# ECM3531 register map
Vendor: EtaCompute; Series: ECM35xx; File version: 1.0.0
CPU: CM3 r1p1, little endian, MPU, no FPU, 3 interrupt priority bits
Registers are 32-bit, read-write, reset 0x0 unless marked. A register's access mark holds for its fields unless they carry their own. Offsets are from the block's base; [hi:lo] are bit positions; 'fields as' and 'values as' point back to an identical list.

## RTC — The real time clock (RTC) is part of the Always On block. In addition to maintaining the real time epoch for the SOC, it also contains all of the control registers of AO block, e.g. registers for the power controller.
Base 0x50010000
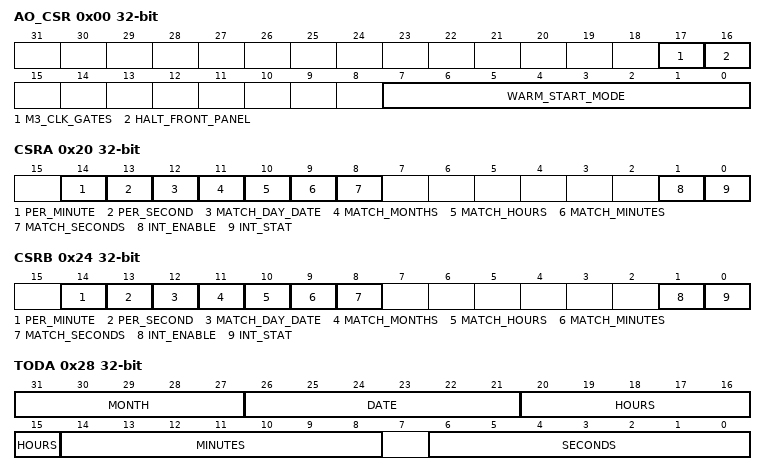
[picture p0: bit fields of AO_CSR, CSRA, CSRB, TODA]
0x00 AO_CSR — Configuration and status bits for the always on block, which includes the RTC, WDT, POWER, etc.
  [17] M3_CLK_GATES — Set this bit to one to keep the M3 clocks running if they would normally be stalled.
  [16] HALT_FRONT_PANEL — Set this bit to one to halt the AO front panel and tristate its output pin for low power reasons.
  [7:0] WARM_START_MODE — BOOTROM assumes 0x00 is a cold start and any non-zero value is a warm start. This value is also visible in the external status register in the GPIO inside the M3 complex. NOTE: a value written to this value survives all resets except the master POR that happens at true first chip power up.
0x20 CSRA — Configuration and status bits for the real time clock (RTC).
  [14] PER_MINUTE — Set to 1 to interrrupt every minute.
  [13] PER_SECOND — Set to 1 to interrrupt every second.
  [12] MATCH_DAY_DATE — Set to 1 to match the day or date.
  [11] MATCH_MONTHS — Set to 1 to match the current month.
  [10] MATCH_HOURS — Set to 1 to match the current hour.
  [9] MATCH_MINUTES — Set to 1 to match the current minutes.
  [8] MATCH_SECONDS — Set to 1 to match the current minutes.
  [1] INT_ENABLE — Interrupt enable bit for ALARM A comparison interrupts.
  [0] INT_STAT — Interrupt status bit for ALARM A comparison (set by an exact match). Write one to this bit to clear it.
0x24 CSRB — Configuration and status bits for the real time clock (RTC).
  [14] PER_MINUTE — Set to 1 to interrrupt every minute.
  [13] PER_SECOND — Set to 1 to interrrupt every second.
  [12] MATCH_DAY_DATE — Set to 1 to match the day or date.
  [11] MATCH_MONTHS — Set to 1 to match the current month.
  [10] MATCH_HOURS — Set to 1 to match the current hour.
  [9] MATCH_MINUTES — Set to 1 to match the current minutes.
  [8] MATCH_SECONDS — Set to 1 to match the current minutes.
  [1] INT_ENABLE — Interrupt enable bit for ALARM B comparison interrupts.
  [0] INT_STAT — Interrupt status bit for ALARM B comparison (set by an exact match). Write one to this bit to clear it.
0x28 TODA — Current time of day as recorded in the RTC. NOTE: This register must be written 32 bits at a time. The counter updates on the last byte written.
  [31:27] MONTH — Current Value of Month (1..12) in the time of day.
  [26:21] DATE — Current Value of Date (0..3,0..9) in the time of day.
  [20:15] HOURS — Current Value of Hours (0..2,0..9) in the time of day.
  [14:8] MINUTES — Current Value of Minutes (0..5,0..9) in the time of day.
  [6:0] SECONDS — Current Value of Seconds(0..5,0..9 in the time of day.
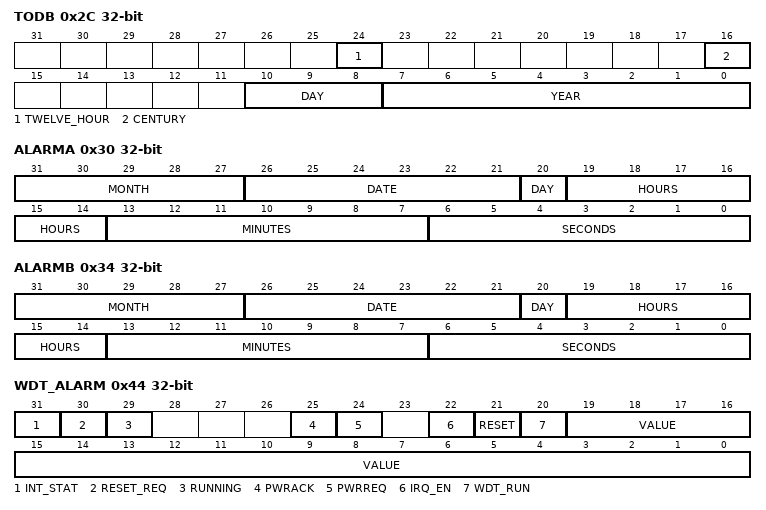
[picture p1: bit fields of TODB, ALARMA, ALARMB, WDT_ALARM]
0x2C TODB — Current time of day as recorded in the RTC. NOTE: Write to Time of Day B (TODB) before writing to Time of Day A (TODA). This register must be written 32 bits at a time. The counter updates on the last byte written.
  [24] TWELVE_HOUR — Set to 1 for 12 hour mode. Set to 0 for 24 hour mode.
  [16] CENTURY — Current Value of Century (0..1) in the time of day.
  [10:8] DAY — Current Value of Year (1..7) in the time of day.
  [7:0] YEAR — Current Value of Year (0..9,0..9) in the time of day.
0x30 ALARMA — ALARM value to match against the current time of day. NOTE: ALARM A interrupt should not be enabled when this register is written. The ALARM A interrupt should be cleared after this register is written.
  [31:27] MONTH — Value of Month (1..12) to be compared against the time of day.
  [26:21] DATE — Value of Date (0..3,0..9) to be compared against the time of day.
  [20] DAY — Set to one to match alarm on day instead of date.
  [19:14] HOURS — Value of Hours (0..2,0..9) to be compared against the time of day.
  [13:7] MINUTES — Value of Minutes (0..5,0..9) to be compared against the time of day.
  [6:0] SECONDS — Value of Seconds(0..5,0..9) to be compared against the time of day.
0x34 ALARMB — ALARM value to match against the current time of day. NOTE: ALARM B interrupt should not be enabled when this register is written. The ALARM B interrupt should be cleared after this register is written.
  fields as ALARMA
0x40 WDT_COUNTER — WDT COUNTER: This register decrements toward zero. If it gets there and resets are enabled then a WDT is issued. This can have the aeffect of waking up the peripheral block and then the M3. The peripheral rstgen status will reflect both a POR and a WDT reset cause in this case. If an interrupt occurs it can also wake up the peripheral block and M3. If the interrupt causes the wake up then it will also be forwarded to the NVIC once the M3 is powered up and out of reset. Write any value to byte 0 of this register to cause the counter to be reloaded from WDT_RELOAD register.
  [19:0] COUNT — Current Value of WDT COUNTER
0x44 WDT_ALARM — WDT ALARM: The contents of this register are matched agains the counter. If the counter value falls below the alarm value then a WDT interrupt status bit is set to one. If this interrupt is enable to cause a power up then the WDT interrupt can power up the peripheral block and the M3.
  [31] INT_STAT — This bit is set to one if a watch dog timer alarm interrupt has been detected. It is clear by writing a one to this bit.
    1=CLEAR (Clear the watch dog timer interrupt status bit.)
  [30] RESET_REQ — This bit is set to one if the watch dog timer counter reaches zero. If the RESET enable bit is also a 1 then this will trigger the cascade of powering up the M3 and then giving it a watch dog timer reset. Firmware can write this bit to either zero or one.
    0=CLEAR (Clear the watch dog timer reset request bit.); 1=SET (Set the watch dog timer reset request bit.)
  [29] RUNNING ro — This bit is set to one if the watch dog timer counter running (decrementing). Clear the enable WDT operation bit reset this read only bit.
  [25] PWRACK ro — This read only bit shows the state of the power up acknowledge sent from the power controller.
  [24] PWRREQ ro — This read only bit shows the state of the power up request sent to the power controller.
  [22] IRQ_EN — Set to one to enable the WDT to interupt the M3. Note an interrupt request will power up the M3 if necessary.
    1=ENABLE (Enable the watch dog timer interrupt.); 0=DISABLE (Disable the watch dog timer interrupt.)
  [21] RESET — Set to one to enable the WDT to reset the chip.
    1=ENABLE (Enable watch dog timer resets.); 0=DISABLE (Disable watch dog timer resets.)
  [20] WDT_RUN — Set to one to enable WDT operation.
    1=ENABLE (Enable the watch dog timer.); 0=DISABLE (Disable the watch dog timer.)
  [19:0] VALUE — Alarm value to compare against the WDT couner.
0x48 WDT_RELOAD — This register holds the value to be reloaded into the counter for each restart of the WDT. Anytime byte 0 of the counter is written then the entire counter is reloaded from this value. In addition, writing to this registers loads the counter from the data written to the RELOAD register. For normal operation, set up the bits in the ALARM register and then write the reload value to this register. This will start the watchdog operation.
  [19:0] VALUE — Load this value into the counter each time a write is directed to byte zero of the counter.
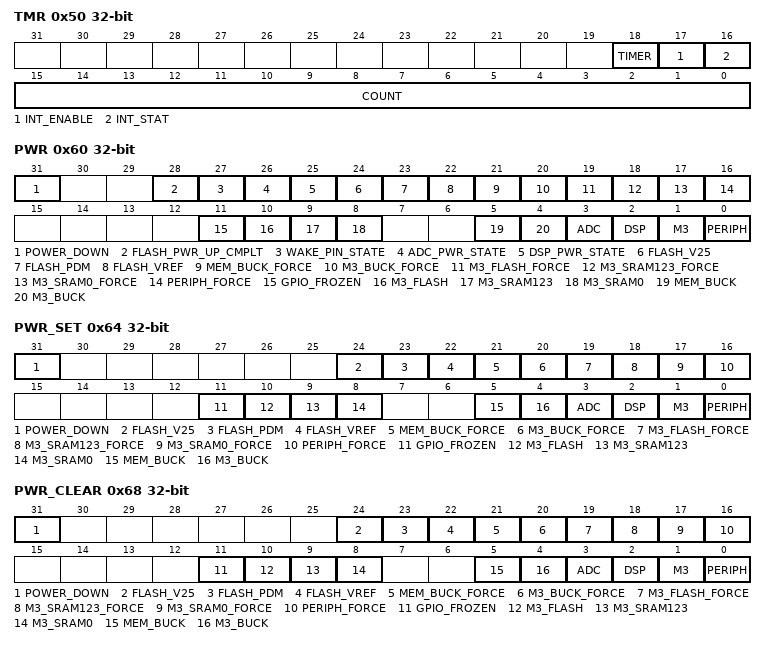
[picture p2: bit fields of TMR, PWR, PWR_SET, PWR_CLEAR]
0x50 TMR — This register controls the 1KHz timer in the always on block. This timer can be used to wake up the M3 from a complete power down state. If the M3 is powered up at the time this timer interrupts, then the M3 simply receives a timer interrupt. NOTE: if the M3 is awakened from a power down state it will receive a full POR restart before it gets the interrupt. The NVIC interrupt enable will have been reset so the interrupt will not fire until the NVIC is re-enabled.
  [18] TIMER — Write a one to this bit to enable the counter to decrement.
    0=STOP (Stop the timer.); 1=RUN (Let the timer run.)
  [17] INT_ENABLE — Write a one to this bit to enable the interrupt status bit to cause an interrupt to the M3 and if necessary, a power up of the M3.
  [16] INT_STAT — This bit is set when the counter decrements from one to zero. It is cleared by writing a one to it.
  [15:0] COUNT — Values written to this bit field update the counter. This counter decrements at a 1KHz rate. When it reaches zero, then its interrupt is generated.
0x60 PWR — This register holds the bit fields that control the power state of the SOC. The default operation when the POWER_DOWN bit is written to one is to turn off ALL power domains except the always on domain. The default behavior on power up is to power up everything but the ADC and the DSP. This can be overridden somewhat using the force bits in this register. The general should only modify the force bits and write to the power down bit. NOTE: the apparent reset or default state of these bits will be different depending on whether the M3 is starting up from a cold start or a warm start.
  [31] POWER_DOWN wo — Write a one to this bit or use the set register to set this bit. Either operation will initiate a power down sequence that will power down the M3 and all of its memories that are to be powered off. If the peripheral power domain is not forced to remain on then it will also be powered down in response to setting this bit. Shutting down the peripheral domain will power down the ADC.
  [28] FLASH_PWR_UP_CMPLT ro — This read only bit indicates when the flash VREF has fully charged and the PDM signal has been removed.
  [27] WAKE_PIN_STATE ro — This read only bit indicates the current value presented to the WAKE pin of the chip. The WAKE pin is one thing that can wake up the M3.
  [26] ADC_PWR_STATE ro — This read only bit indicates the current power state of the ADC. In general, the power on of the ADC will appear to be instantaneous to an M3 program. This bit provides a mechanism to interlock the firmware power up code.
  [25] DSP_PWR_STATE ro — This read only bit indicates the current power state of the DSP. In general, the power on of the DSP will appear to be instantaneous to an M3 program. This bit provides a mechanism to interlock the firmware power up code.
  [24] FLASH_V25 — Set this bit to zero to turn off the flash FLASH 2.5V. Set this bit to one to turn on the FLASH 2.5V.
  [23] FLASH_PDM — Set this bit to zero to turn off the flash PDM signal.
  [22] FLASH_VREF — Set this bit to zero to turn off the voltage reference for the flash.
  [21] MEM_BUCK_FORCE — Write a one to this bit to force the MEM BUCK converter to remain ON even when the M3 itself is powered OFF. The default behavior is to power down the MEM BUCK converter when the M3 powers off.
  [20] M3_BUCK_FORCE — Write a one to this bit to force the M3 BUCK converter to remain ON even when the M3 itself is powered OFF. The default behavior is to power down the M3 BUCK converter when the M3 powers off.
  [19] M3_FLASH_FORCE — Write a one to this bit to force the M3 FLASH power domain to remain OFF even when the M3 itself is powered back up.
  [18] M3_SRAM123_FORCE — Write a one to this bit to force the M3 SRAM123 power domain to remain ON even when the M3 itself is powered down.
  [17] M3_SRAM0_FORCE — Write a one to this bit to force the M3 SRAM0 power domain to remain ON even when the M3 itself is powered down.
  [16] PERIPH_FORCE — Write a one to this bit to force the PERIPH power domain to remain ON even when the M3, DSP, and ADC are powered down.
  [11] GPIO_FROZEN — Write a zero to this bit to force the GPIO latch in the peripheral block to flow through to the pins again. The GPIO data out enable out type signals are frozen in their final state before the M3 is reset, isolated and powered. This happens automatically on a power down of the M3. When the M3 comes back in a warm start the GPIO latches are frozen until firmware clears this bit. A cold start does not set hthis bit.
  [10] M3_FLASH — Write a zero to this bit to turn off power in the M3 FLASH power domain. This bit is set automatically at initial power provisioning. Can be turned back on automatically in response to a wake up event. In addition, this bit can be forced to remain off even if the M3 is powered up from a wake event. This is useful for various power saving modes where the program is running as a warm start program in one or more of the SRAMs.
  [9] M3_SRAM123 — Write a zero to this bit to turn off power in the M3 SRAM123 power domain. This bit is set automatically at initial power provisioning. Can be turned back on automatically in response to a wake up event. In addition, this bit can be forced to remain on even if the M3 is powered down.
  [8] M3_SRAM0 — Write a zero to this bit to turn off power in the M3 SRAM0 power domain. This bit is set automatically at initial power provisioning. Can be turned back on automatically in response to a wake up event. In addition, this bit can be forced to remain on even if the M3 is powered down.
  [5] MEM_BUCK — Write a zero to this bit to turn off the MEM BUCK converter.
  [4] M3_BUCK — Write a zero to this bit to turn off the M3 BUCK converter.
  [3] ADC — Write a zero to this bit to turn off power in the ADC power domain. This bit is NOT set automatically at initial power provisioning. It can *NOT* be turned back on automatically in response to a wake up event. It can, however, be left on during an M3 power request. This would only make since if peripheral power were left on. Thus turning off the peripheral power will this area of the chip off as well.
  [2] DSP — Write a zero to this bit to turn off power in the DSP power domain. Writing zero will also power down the DSP SRAMs. This bit is NOT set automatically at initial power provisioning. It can *NOT* be turned back on automatically in response to a wake up event. It is ALWAYS automatically turned off as part of every power down sequence. This bit also controls the power state of the DSP PMEM, XMEM, and YMEM.
  [1] M3 — Write a zero to this bit to turn off power in the M3 power domain. Writing zero will also power down the M3 SRAMs, Flash, and Bootrom. This bit is set automatically at initial power provisioning. Can be turned back on automatically in response to a wake up event.
  [0] PERIPH — Write a zero to this bit to turn off power in the peripheral power domain. This bit is set automatically at initial power provisioning. Can be turned back on automatically in response to a wake up event. Note that turning on this bit will also turn on the high frequency oscillator (HFO).
0x64 PWR_SET — The bits in this register correspond to bits in the PWR register. Writing a one to one of the bits in this register cause the correponding bit in the PWR register to be set. These bits always read back as zero.
  [31] POWER_DOWN wo — Writing a one to this bit will initiate a power down sequence.
  [24] FLASH_V25 wo — Writing a one to this bit will set the corresponding bit in the PWR register.
  [23] FLASH_PDM wo — Writing a one to this bit will set the corresponding bit in the PWR register.
  [22] FLASH_VREF wo — Set this bit to zero to turn of the voltage reference for the flash.
  [21] MEM_BUCK_FORCE wo — Writing a one to this bit will set the corresponding bit in the PWR register.
  [20] M3_BUCK_FORCE wo — Writing a one to this bit will set the corresponding bit in the PWR register.
  [19] M3_FLASH_FORCE wo — Writing a one to this bit will set the corresponding bit in the PWR register.
  [18] M3_SRAM123_FORCE wo — Writing a one to this bit will set the corresponding bit in the PWR register.
  [17] M3_SRAM0_FORCE wo — Writing a one to this bit will set the corresponding bit in the PWR register.
  [16] PERIPH_FORCE wo — Writing a one to this bit will set the corresponding bit in the PWR register.
  [11] GPIO_FROZEN wo — Writing a one to this bit will set the corresponding bit in the PWR register.
  [10] M3_FLASH wo — Writing a one to this bit will set the corresponding bit in the PWR register.
  [9] M3_SRAM123 wo — Writing a one to this bit will set the corresponding bit in the PWR register.
  [8] M3_SRAM0 wo — Writing a one to this bit will set the corresponding bit in the PWR register.
  [5] MEM_BUCK — Write a one to this bit will set the corresponding bit in the PWR register.
  [4] M3_BUCK — Write a one to this bit will set the corresponding bit in the PWR register.
  [3] ADC wo — Writing a one to this bit will set the corresponding bit in the PWR register.
  [2] DSP wo — Writing a one to this bit will set the corresponding bit in the PWR register.
  [1] M3 wo — Writing a one to this bit will set the corresponding bit in the PWR register.
  [0] PERIPH wo — Writing a one to this bit will set the corresponding bit in the PWR register.
0x68 PWR_CLEAR — The bits in this register correspond to bits in the PWR register. Writing a one to one of the bits in this register cause the correponding bit in the PWR register to be cleared. These bits always read back as zero.
  [31] POWER_DOWN wo — Writing a one to this bit will have no effect.
  [24] FLASH_V25 wo — Writing a one to this bit will clear the corresponding bit in the PWR register.
  [23] FLASH_PDM wo — Writing a one to this bit will clear the corresponding bit in the PWR register.
  [22] FLASH_VREF wo — Set this bit to zero to turn of the voltage reference for the flash.
  [21] MEM_BUCK_FORCE — Writing a one to this bit will clear the corresponding bit in the PWR register.
  [20] M3_BUCK_FORCE — Writing a one to this bit will clear the corresponding bit in the PWR register.
  [19] M3_FLASH_FORCE wo — Writing a one to this bit will clear the corresponding bit in the PWR register.
  [18] M3_SRAM123_FORCE wo — Writing a one to this bit will clear the corresponding bit in the PWR register.
  [17] M3_SRAM0_FORCE wo — Writing a one to this bit will clear the corresponding bit in the PWR register.
  [16] PERIPH_FORCE wo — Writing a one to this bit will clear the corresponding bit in the PWR register.
  [11] GPIO_FROZEN wo — Writing a one to this bit will clear the corresponding bit in the PWR register.
  [10] M3_FLASH wo — Writing a one to this bit will clear the corresponding bit in the PWR register.
  [9] M3_SRAM123 wo — Writing a one to this bit will clear the corresponding bit in the PWR register.
  [8] M3_SRAM0 wo — Writing a one to this bit will clear the corresponding bit in the PWR register.
  [5] MEM_BUCK — Write a one to this bit will clear the corresponding bit in the PWR register.
  [4] M3_BUCK — Write a one to this bit will clear the corresponding bit in the PWR register.
  [3] ADC wo — Writing a one to this bit will clear the corresponding bit in the PWR register.
  [2] DSP wo — Writing a one to this bit will clear the corresponding bit in the PWR register.
  [1] M3 wo — Writing a one to this bit will clear the corresponding bit in the PWR register.
  [0] PERIPH wo — Writing a one to this bit will clear the corresponding bit in the PWR register.
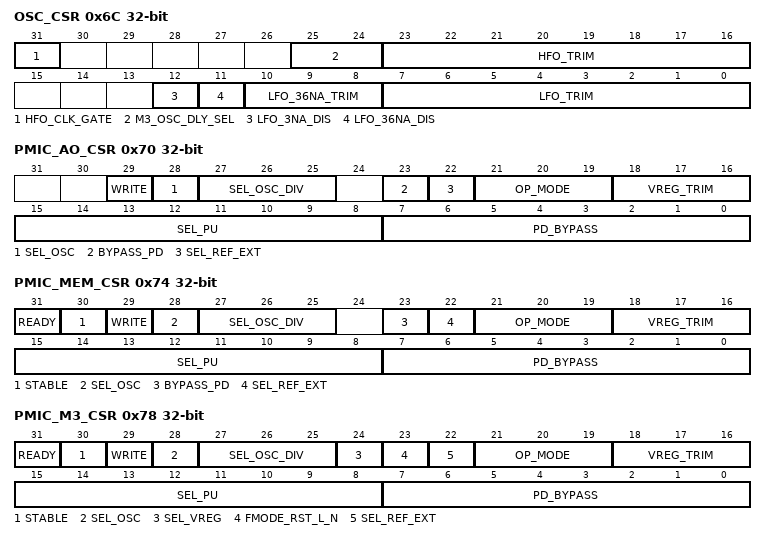
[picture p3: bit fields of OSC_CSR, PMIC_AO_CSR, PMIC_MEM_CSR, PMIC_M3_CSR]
0x6C OSC_CSR — Control bits headed either for the 8MHz high frequency osciallator (HFO) or to the 32KHz low frequency oscillator (LFO).
  [31] HFO_CLK_GATE — Writing a one to this bit will stop the HFO clock while it's trim values are changed. Firmware has to stop this clock when changing the value in the HFO_TRIM and HFO_TRIM_DIV bit fields.
  [25:24] M3_OSC_DLY_SEL — These settings will be defined after characterization.
  [23:16] HFO_TRIM — These settings will be defined after characterization.
  [12] LFO_3NA_DIS — Set to one to disable voltage mode operation reference current.
  [11] LFO_36NA_DIS — Set to one to disable current mode operation reference current.
  [10:8] LFO_36NA_TRIM — Set the current mode reference trim value into this bit field. These settings will be defined after characterization.
  [7:0] LFO_TRIM — Output frequency trim settings. These settings will be defined after characterization.
0x70 PMIC_AO_CSR — Control bits headed for the PMIC. These are all captured in the PMIC by LOAD_L. The LOAD_L pulse is automatically generated whenever this register is written, provided that the WRITE bit is written as a one on the same cycle.
  [29] WRITE wo — Set this write only bit to one to issue a LOAD_L pulse to the PMIC causing it to capture the values from this register.
  [28] SEL_OSC — Selects which clock source to use for the divider in the peripheral which can drive the AO PMIC.
    0=HFO (Select the 8MHz HFO clock source into the divider.); 1=XTAL (Select the 32KHz clock source into the divider.)
  [27:25] SEL_OSC_DIV — Selects which HFO divider to use as an external clock for this PMIC.
    0=1BY1 (Divider is set for 1 divided by 1, i.e. 1MHz or 32768Hz.); 1=1BY2 (Divider is set for 1 divided by 2, i.e. 500KHz or 16384Hz.); 2=1BY4 (Divider is set for 1 divided by 4, i.e. 250KHz or 8192Hz.); 3=1BY8 (Divider is set for 1 divided by 8, i.e. 125KHz or 4096Hz.); 4=1BY16 (Divider is set for 1 divided by 16, i.e. 62500Hz or 2048Hz.); 5=1BY32 (Divider is set for 1 divided by 32, i.e. 1024Hz (only 32KHz source).); 6=1BY64 (Divider is set for 1 divided by 64, i.e. 512Hz (only 32KHz source).); 7=1BY128 (Divider is set for 1 divided by 128, i.e. 256Hz (only 32KHz source).)
  [23] BYPASS_PD — Inside the PMIC, this value bypasses the normal internal generation of the pull down pulse width. It substitutes the PD_BYPASS value instead.
    0=NORMAL (Select normal operation in which PMIC controls pull down pulse width.); 1=OVERRIDE (OVERRIDE automatic control function in PMIC.)
  [22] SEL_REF_EXT — Inside the PMIC, this value selects between REF_CLK_PWR_UP and REF_CLK input to the PMIC.
    0=INITIAL (Select initial operation by using the internal reference clock.); 1=NORMAL (Select the reference clock that is supplied to the PMIC block.)
  [21:19] OP_MODE — Inside the PMIC, this value selects between frequency and voltage mode and selects the target voltage in voltage mode.
    0=VOLTAGE_600MV (Select voltage mode and target 600mV.); 1=VOLTAGE_700MV (Select voltage mode and target 700mV.); 2=VOLTAGE_900MV (Select voltage mode and target 900mV.); 3=VOLTAGE_1200MV (Select voltage mode and target 1200mV.); 4=FREQUENCY_MODE (Select frequency mode with VMIN and VMAX protection.); 5=FREQ_VMIN (Select frequency mode with VMIN protection.); 6=FREQ_VMAX (Select frequency mode with maximum voltage limiting to XXXmV.); 7=FREQUENCY_NO_VLIM (Select frequency mode with NO minimum or maximum voltage limiting.)
  [18:16] VREG_TRIM — Inside the PMIC, this value selects a trim offset for the target voltage.
  [15:8] SEL_PU — Inside the PMIC, this value controls the switch drivers UP pulse width. It defaults to the 900mV setting at reset. This value is ignored during initialization.
  [7:0] PD_BYPASS — Inside the PMIC, this value controls the switch drivers DOWN pulse width. This value is only used in the driver if BYPASS_PD is also a one.
0x74 PMIC_MEM_CSR — Control bits headed for the PMIC. These are all captured in the PMIC by LOAD_L. The LOAD_L pulse is automatically generated whenever this register is written, provided that the WRITE bit is written as a one on the same cycle.
  [31] READY ro — The PMIC reports not ready, 0x0, whenever it is powered up. Firmware can use this bit to know when the target voltage has been reached.
  [30] STABLE ro — This bit reports not stable, 0x0, whenever its target voltage is changed by firmware. Firmware can use this bit to know when the target voltage has been reached.
  [29] WRITE wo — Set this write only bit to one to issue a LOAD_L pulse to the PMIC causing it to capture the values from this register.
  [28] SEL_OSC — Selects which clock source to use for the divider in the peripheral which can drive the MEM PMIC.
    values as PMIC_AO_CSR.SEL_OSC
  [27:25] SEL_OSC_DIV — Selects which HFO divider to use as an external clock for this PMIC.
    values as PMIC_AO_CSR.SEL_OSC_DIV
  [23] BYPASS_PD — Inside the PMIC, this value bypasses the normal internal generation of the pull down pulse width. It substitutes the PD_BYPASS value instead.
    values as PMIC_AO_CSR.BYPASS_PD
  [22] SEL_REF_EXT — Inside the PMIC, this value selects between REF_CLK_PWR_UP and REF_CLK input to the PMIC.
    values as PMIC_AO_CSR.SEL_REF_EXT
  [21:19] OP_MODE — Inside the PMIC, this value selects between frequency and voltage mode and selects the target voltage in voltage mode.
    values as PMIC_AO_CSR.OP_MODE
  [18:16] VREG_TRIM — Inside the PMIC, this value selects a trim offset for the target voltage.
  [15:8] SEL_PU — Inside the PMIC, this value controls the switch drivers UP pulse width. It defaults to the 900mV setting at reset. This value is ignored during initialization.
  [7:0] PD_BYPASS — Inside the PMIC, this value controls the switch drivers DOWN pulse width. This value is only used in the driver if BYPASS_PD is also a one.
0x78 PMIC_M3_CSR — Control bits headed for the PMIC. These are all captured in the PMIC by LOAD_L. The LOAD_L pulse is automatically generated whenever this register is written, provided that the WRITE bit is written as a one on the same cycle.
  [31] READY ro — The PMIC reports not ready, 0x0, whenever it is powered up. Firmware can use this bit to know when the target voltage has been reached.
  [30] STABLE ro — This bit reports not stable, 0x0, whenever its target voltage is changed by firmware. Firmware can use this bit to know when the target voltage has been reached.
  [29] WRITE wo — Set this write only bit to one to issue a LOAD_L pulse to the PMIC causing it to capture the values from this register.
  [28] SEL_OSC — Selects which clock source to use for the divider in the peripheral which can drive the M3 PMIC.
    values as PMIC_AO_CSR.SEL_OSC
  [27:25] SEL_OSC_DIV — Selects which HFO divider to use as an external clock for this PMIC.
    values as PMIC_AO_CSR.SEL_OSC_DIV
  [24] SEL_VREG — Set to one to monitor VDD_M3 after the power switch. Set to zero to monitor before the switch.
    0=REG_OUTPUT (Select monitoring the regulator output.); 1=POST_SWITCH (Select monitoring the voltage after it is switched.)
  [23] FMODE_RST_L_N — Inside the PMIC, this value forces a reset to the frequency mode counters. This should be 0 before switching to frequency mode. After the switch this should be set to one.
    1=RESET (Select RESET operation for the frequency mode of operation.); 0=NORMAL (Select NORMAL operation for the frequency mode of operation.)
  [22] SEL_REF_EXT — Inside the PMIC, this value selects between REF_CLK_PWR_UP and REF_CLK input to the PMIC.
    values as PMIC_AO_CSR.SEL_REF_EXT
  [21:19] OP_MODE — Inside the PMIC, this value selects between frequency and voltage mode and selects the target voltage in voltage mode.
    values as PMIC_AO_CSR.OP_MODE
  [18:16] VREG_TRIM — Inside the PMIC, this value selects a trim offset for the target voltage.
  [15:8] SEL_PU — Inside the PMIC, this value controls the switch drivers UP pulse width. It defaults to the 900mV setting at reset. This value is ignored during initialization.
  [7:0] PD_BYPASS — Inside the PMIC, this value controls the switch drivers DOWN pulse width. This value is only used in the driver if BYPASS_PD is also a one.
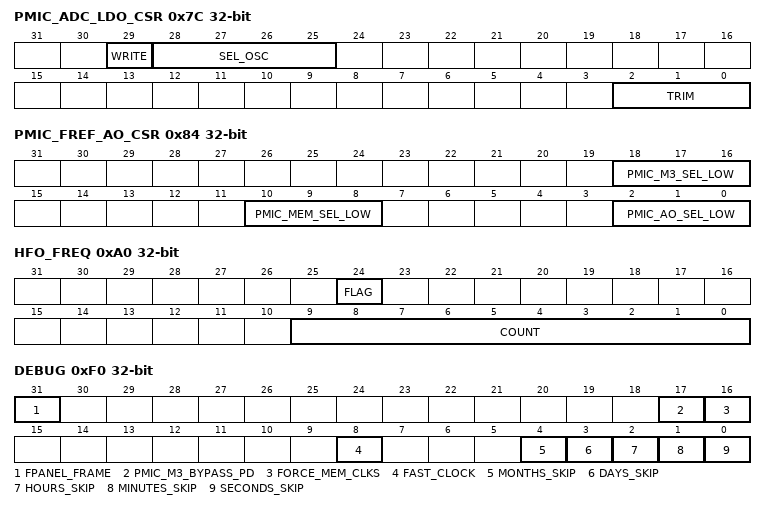
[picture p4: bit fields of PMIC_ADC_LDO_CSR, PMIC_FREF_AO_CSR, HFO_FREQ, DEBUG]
0x7C PMIC_ADC_LDO_CSR — Control bits headed for the ADC LDO. These are all captured in the LDO by LOAD_L. The LOAD_L pulse is automatically generated whenever this register is written, provided that the WRITE bit is written as a one on the same cycle.
  [29] WRITE wo — Set this write only bit to one to issue a LOAD_L pulse to the PMIC causing it to capture the values from this register.
  [28:25] SEL_OSC — Selects which HFO divider to use as an external clock for this digital LDO. FIXME BRYAN set enums for divisions.
  [2:0] TRIM — Selects a trim value for the ADC LDO. Note this value has to be loaded into the LDO control latches to take effect.
0x80 PMIC_M3_CSR2 — This register contains the frequency target value for the M3 PMIC.
  [7:0] FREQ_TARGET — This field defines the target frequency of the M3 PMIC based on this equation: FREQ_TARGET = ((Oscillator Clock / Reference Clock) / 2)
0x84 PMIC_FREF_AO_CSR — This register contains the AO state dividers for the 3 PMIC clock references.
  [18:16] PMIC_M3_SEL_LOW — This field defines the frequency divider applied to the 32KHz low frequency reference.
    0=1BY1 (Divider is set for 1 divided by 1, i.e. 32768Hz.); 1=1BY2 (Divider is set for 1 divided by 2, i.e. 16384Hz.); 2=1BY4 (Divider is set for 1 divided by 4, i.e. 8192Hz.); 3=1BY8 (Divider is set for 1 divided by 8, i.e. 4096Hz.); 4=1BY16 (Divider is set for 1 divided by 16, i.e. 2048Hz.); 5=1BY32 (Divider is set for 1 divided by 32, i.e. 1024Hz.); 6=1BY64 (Divider is set for 1 divided by 64, i.e. 512Hz.); 7=1BY128 (Divider is set for 1 divided by 128, i.e. 256Hz.)
  [10:8] PMIC_MEM_SEL_LOW — This field defines the frequency divider applied to the 32KHz low frequency reference.
    values as PMIC_M3_SEL_LOW
  [2:0] PMIC_AO_SEL_LOW — This field defines the frequency divider applied to the 32KHz low frequency reference.
    0=1BY1 (Divider is set for 1 divided by 1, i.e. 32768Hz.); 1=1BY2 (Divider is set for 1 divided by 2, i.e. 16384Hz.); 2=1BY4 (Divider is set for 1 divided by 4, i.e. 8192Hz.); 3=1BY8 (Divider is set for 1 divided by 8, i.e. 4096Hz.); 4=1BY16 (Divider is set for 1 divided by 16, i.e. 2048Hz.); 5=1BY32 (Divider is set for 1 divided by 32, i.e. 1024Hz.); 6=1BY64 (Divider is set for 1 divided by 62, i.e. 512Hz.); 7=1BY128 (Divider is set for 1 divided by 128, i.e. 256Hz.)
0xA0 HFO_FREQ — This register contains the frequency counter for the HFO. It counts the number of HFO clocks that occur between two rising edges of the 32KHz clock. NOTE: while this counter measures for the period of one 32KHz clock it does not do it every clock. This register will update every 4 32KHz clocks.
  [24] FLAG ro — This toggles for every counter update (once every 4x32KHz clocks).
  [9:0] COUNT ro — This counter tells the approximate frequency of the HFO.
0xE0 NVRAMA — This register holds a 32-bit value for the application in 32-bits of non-volatile storage. NOTE: a value written to this register survives all resets except the master POR that happens at true first chip power up.
  [31:0] VALUE — 32-bits of non-volatile storage.
0xE4 NVRAMB — This register holds a 32-bit value for the application in 32-bits of non-volatile storage. NOTE: a value written to this register survives all resets except the master POR that happens at true first chip power up.
  [31:0] VALUE — 32-bits of non-volatile storage.
0xE8 NVRAMC — This register holds a 32-bit value for the application in 32-bits of non-volatile storage. NOTE: a value written to this register survives all resets except the master POR that happens at true first chip power up.
  [31:0] VALUE — 32-bits of non-volatile storage.
0xEC NVRAMD — This register holds a 32-bit value for the application in 32-bits of non-volatile storage. NOTE: a value written to this register survives all resets except the master POR that happens at true first chip power up.
  [31:0] VALUE — 32-bits of non-volatile storage.
0xF0 DEBUG — Provide debug controls for the blocks in the always on block.
  [31] FPANEL_FRAME ro — Use this bit in diagnostics to count front panel frames.
  [17] PMIC_M3_BYPASS_PD — Inside the M3 PMIC, this value bypasses the normal internal generation of the pull down pulse width. It substitutes the PD_BYPASS value instead.
    values as PMIC_AO_CSR.BYPASS_PD
  [16] FORCE_MEM_CLKS — Force memory clocks to remain on. This one resets to one to guarantee memories will come up.
  [8] FAST_CLOCK — Select fast clock for time of day testing and debug.
  [4] MONTHS_SKIP — Assume a carry out on every RTC increment. Makes years pass by in seconds.
  [3] DAYS_SKIP — Assume a carry out on every RTC increment.
  [2] HOURS_SKIP — Assume a carry out on every RTC increment. Makes days pass by in seconds.
  [1] MINUTES_SKIP — Assume a carry out on every RTC increment. Makes hours pass by in seconds.
  [0] SECONDS_SKIP — Assume a carry out on every RTC increment. Makes minutes pass by in seconds.
0xF4 DEBUG_READ_WRITE — Provide a read/write register for diagnostics.
  [31:0] VALUE — Debug Read/Write Register for Diagnostics.
0xF8 DEBUG0_READ_ONLY — Provide a read only value for diagnostics.
  [31:0] VALUE ro — Debug Read Only Value for Diagnostics.
0xFC DEBUG1_READ_ONLY — Provide a read only value for diagnostics.
  [31:0] VALUE ro — Debug Read Only Value for Diagnostics.
